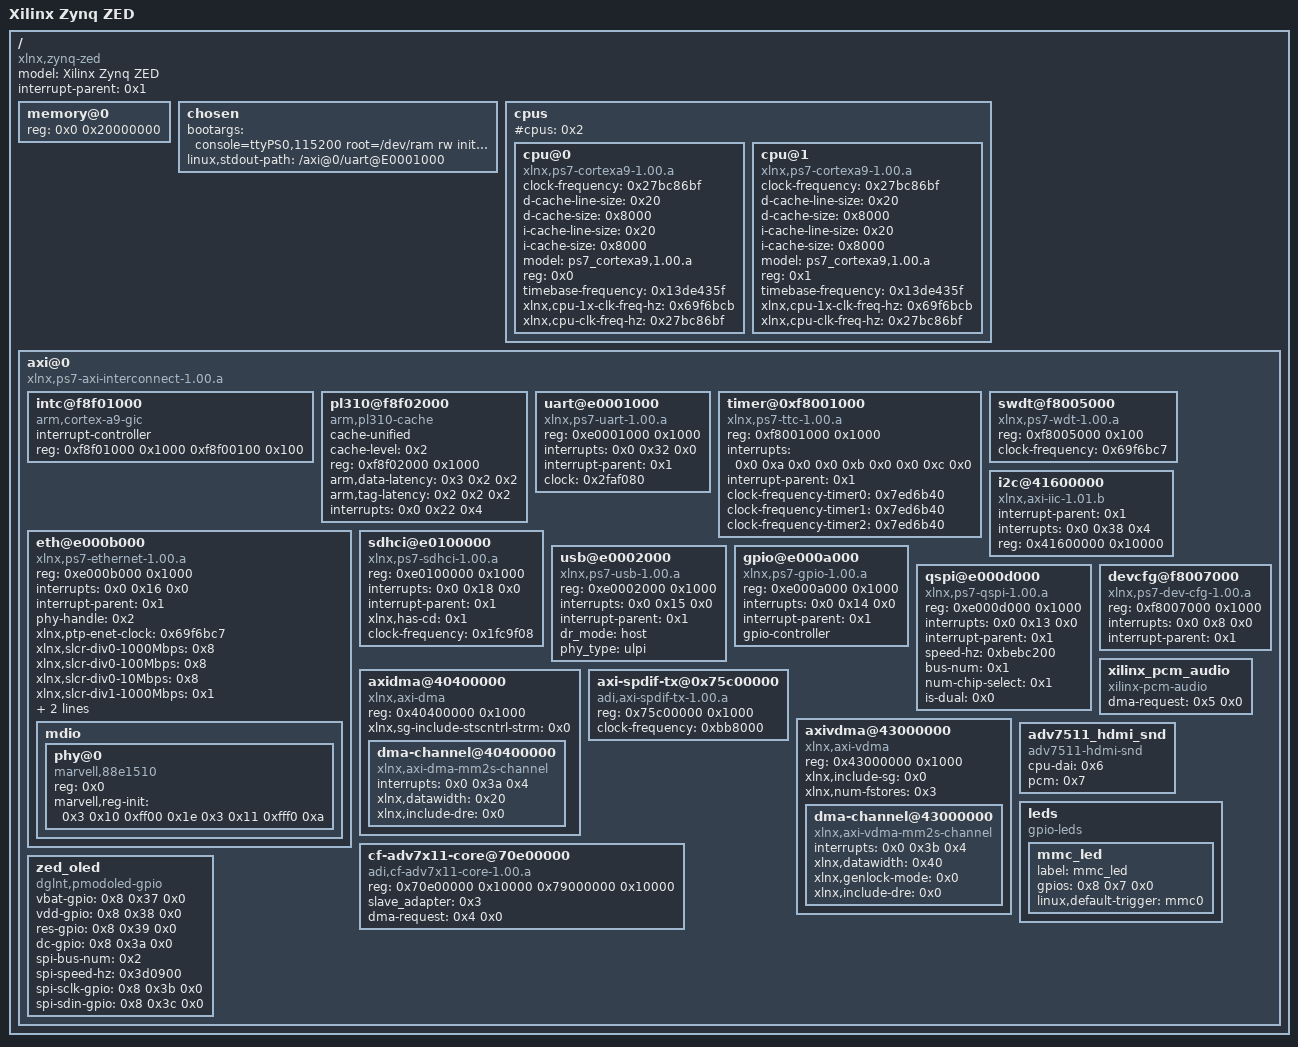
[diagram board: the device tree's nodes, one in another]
/dts-v1/;

/ {
	model = "Xilinx Zynq ZED";
	compatible = "xlnx,zynq-zed";
	#address-cells = <0x1>;
	#size-cells = <0x1>;
	interrupt-parent = <0x1>;

	memory@0 {
		device_type = "memory";
		reg = <0x0 0x20000000>;
	};

	chosen {
		bootargs = "console=ttyPS0,115200 root=/dev/ram rw initrd=0x800000,8M earlyprintk rootfstype=ext4 rootwait devtmpfs.mount=0";
		linux,stdout-path = "/axi@0/uart@E0001000";
	};

	cpus {
		#address-cells = <0x1>;
		#cpus = <0x2>;
		#size-cells = <0x0>;

		cpu@0 {
			clock-frequency = <0x27bc86bf>;
			compatible = "xlnx,ps7-cortexa9-1.00.a";
			d-cache-line-size = <0x20>;
			d-cache-size = <0x8000>;
			device_type = "cpu";
			i-cache-line-size = <0x20>;
			i-cache-size = <0x8000>;
			model = "ps7_cortexa9,1.00.a";
			reg = <0x0>;
			timebase-frequency = <0x13de435f>;
			xlnx,cpu-1x-clk-freq-hz = <0x69f6bcb>;
			xlnx,cpu-clk-freq-hz = <0x27bc86bf>;
		};

		cpu@1 {
			clock-frequency = <0x27bc86bf>;
			compatible = "xlnx,ps7-cortexa9-1.00.a";
			d-cache-line-size = <0x20>;
			d-cache-size = <0x8000>;
			device_type = "cpu";
			i-cache-line-size = <0x20>;
			i-cache-size = <0x8000>;
			model = "ps7_cortexa9,1.00.a";
			reg = <0x1>;
			timebase-frequency = <0x13de435f>;
			xlnx,cpu-1x-clk-freq-hz = <0x69f6bcb>;
			xlnx,cpu-clk-freq-hz = <0x27bc86bf>;
		};
	};

	axi@0 {
		#address-cells = <0x1>;
		#size-cells = <0x1>;
		compatible = "xlnx,ps7-axi-interconnect-1.00.a", "simple-bus";
		ranges;

		intc@f8f01000 {
			interrupt-controller;
			compatible = "arm,cortex-a9-gic";
			#interrupt-cells = <0x3>;
			reg = <0xf8f01000 0x1000 0xf8f00100 0x100>;
			linux,phandle = <0x1>;
			phandle = <0x1>;
		};

		pl310@f8f02000 {
			compatible = "arm,pl310-cache";
			cache-unified;
			cache-level = <0x2>;
			reg = <0xf8f02000 0x1000>;
			arm,data-latency = <0x3 0x2 0x2>;
			arm,tag-latency = <0x2 0x2 0x2>;
			interrupts = <0x0 0x22 0x4>;
		};

		uart@e0001000 {
			compatible = "xlnx,ps7-uart-1.00.a";
			reg = <0xe0001000 0x1000>;
			interrupts = <0x0 0x32 0x0>;
			interrupt-parent = <0x1>;
			clock = <0x2faf080>;
		};

		timer@0xf8001000 {
			compatible = "xlnx,ps7-ttc-1.00.a";
			reg = <0xf8001000 0x1000>;
			interrupts = <0x0 0xa 0x0 0x0 0xb 0x0 0x0 0xc 0x0>;
			interrupt-parent = <0x1>;
			clock-frequency-timer0 = <0x7ed6b40>;
			clock-frequency-timer1 = <0x7ed6b40>;
			clock-frequency-timer2 = <0x7ed6b40>;
		};

		swdt@f8005000 {
			device_type = "watchdog";
			compatible = "xlnx,ps7-wdt-1.00.a";
			reg = <0xf8005000 0x100>;
			clock-frequency = <0x69f6bc7>;
		};

		eth@e000b000 {
			compatible = "xlnx,ps7-ethernet-1.00.a";
			reg = <0xe000b000 0x1000>;
			interrupts = <0x0 0x16 0x0>;
			interrupt-parent = <0x1>;
			phy-handle = <0x2>;
			#address-cells = <0x1>;
			#size-cells = <0x0>;
			xlnx,ptp-enet-clock = <0x69f6bc7>;
			xlnx,slcr-div0-1000Mbps = <0x8>;
			xlnx,slcr-div0-100Mbps = <0x8>;
			xlnx,slcr-div0-10Mbps = <0x8>;
			xlnx,slcr-div1-1000Mbps = <0x1>;
			xlnx,slcr-div1-100Mbps = <0x5>;
			xlnx,slcr-div1-10Mbps = <0x32>;

			mdio {
				#address-cells = <0x1>;
				#size-cells = <0x0>;

				phy@0 {
					compatible = "marvell,88e1510";
					device_type = "ethernet-phy";
					reg = <0x0>;
					marvell,reg-init = <0x3 0x10 0xff00 0x1e 0x3 0x11 0xfff0 0xa>;
					linux,phandle = <0x2>;
					phandle = <0x2>;
				};
			};
		};

		i2c@41600000 {
			compatible = "xlnx,axi-iic-1.01.b", "xlnx,xps-iic-2.00.a";
			interrupt-parent = <0x1>;
			interrupts = <0x0 0x38 0x4>;
			reg = <0x41600000 0x10000>;
			#size-cells = <0x0>;
			#address-cells = <0x1>;
			linux,phandle = <0x3>;
			phandle = <0x3>;
		};

		sdhci@e0100000 {
			compatible = "xlnx,ps7-sdhci-1.00.a";
			reg = <0xe0100000 0x1000>;
			interrupts = <0x0 0x18 0x0>;
			interrupt-parent = <0x1>;
			xlnx,has-cd = <0x1>;
			clock-frequency = <0x1fc9f08>;
		};

		usb@e0002000 {
			compatible = "xlnx,ps7-usb-1.00.a";
			reg = <0xe0002000 0x1000>;
			interrupts = <0x0 0x15 0x0>;
			interrupt-parent = <0x1>;
			dr_mode = "host";
			phy_type = "ulpi";
		};

		gpio@e000a000 {
			compatible = "xlnx,ps7-gpio-1.00.a";
			#gpio-cells = <0x2>;
			reg = <0xe000a000 0x1000>;
			interrupts = <0x0 0x14 0x0>;
			interrupt-parent = <0x1>;
			gpio-controller;
			linux,phandle = <0x8>;
			phandle = <0x8>;
		};

		qspi@e000d000 {
			compatible = "xlnx,ps7-qspi-1.00.a";
			reg = <0xe000d000 0x1000>;
			interrupts = <0x0 0x13 0x0>;
			interrupt-parent = <0x1>;
			speed-hz = <0xbebc200>;
			bus-num = <0x1>;
			num-chip-select = <0x1>;
			is-dual = <0x0>;
		};

		devcfg@f8007000 {
			compatible = "xlnx,ps7-dev-cfg-1.00.a";
			reg = <0xf8007000 0x1000>;
			interrupts = <0x0 0x8 0x0>;
			interrupt-parent = <0x1>;
		};

		axidma@40400000 {
			#address-cells = <0x1>;
			#size-cells = <0x1>;
			#dma-cells = <0x1>;
			compatible = "xlnx,axi-dma";
			reg = <0x40400000 0x1000>;
			xlnx,sg-include-stscntrl-strm = <0x0>;
			linux,phandle = <0x5>;
			phandle = <0x5>;

			dma-channel@40400000 {
				compatible = "xlnx,axi-dma-mm2s-channel";
				interrupts = <0x0 0x3a 0x4>;
				xlnx,datawidth = <0x20>;
				xlnx,include-dre = <0x0>;
			};
		};

		axi-spdif-tx@0x75c00000 {
			compatible = "adi,axi-spdif-tx-1.00.a";
			reg = <0x75c00000 0x1000>;
			clock-frequency = <0xbb8000>;
			linux,phandle = <0x6>;
			phandle = <0x6>;
		};

		axivdma@43000000 {
			#address-cells = <0x1>;
			#size-cells = <0x1>;
			#dma-cells = <0x1>;
			compatible = "xlnx,axi-vdma";
			reg = <0x43000000 0x1000>;
			xlnx,include-sg = <0x0>;
			xlnx,num-fstores = <0x3>;
			linux,phandle = <0x4>;
			phandle = <0x4>;

			dma-channel@43000000 {
				compatible = "xlnx,axi-vdma-mm2s-channel";
				interrupts = <0x0 0x3b 0x4>;
				xlnx,datawidth = <0x40>;
				xlnx,genlock-mode = <0x0>;
				xlnx,include-dre = <0x0>;
			};
		};

		cf-adv7x11-core@70e00000 {
			compatible = "adi,cf-adv7x11-core-1.00.a";
			reg = <0x70e00000 0x10000 0x79000000 0x10000>;
			slave_adapter = <0x3>;
			dma-request = <0x4 0x0>;
		};

		xilinx_pcm_audio {
			compatible = "xilinx-pcm-audio";
			dma-request = <0x5 0x0>;
			linux,phandle = <0x7>;
			phandle = <0x7>;
		};

		adv7511_hdmi_snd {
			compatible = "adv7511-hdmi-snd";
			cpu-dai = <0x6>;
			pcm = <0x7>;
		};

		leds {
			compatible = "gpio-leds";

			mmc_led {
				label = "mmc_led";
				gpios = <0x8 0x7 0x0>;
				linux,default-trigger = "mmc0";
			};
		};

		zed_oled {
			compatible = "dglnt,pmodoled-gpio";
			vbat-gpio = <0x8 0x37 0x0>;
			vdd-gpio = <0x8 0x38 0x0>;
			res-gpio = <0x8 0x39 0x0>;
			dc-gpio = <0x8 0x3a 0x0>;
			spi-bus-num = <0x2>;
			spi-speed-hz = <0x3d0900>;
			spi-sclk-gpio = <0x8 0x3b 0x0>;
			spi-sdin-gpio = <0x8 0x3c 0x0>;
		};
	};
};
